VERSION ""

NS_ :

BS_:

BU_: Vector__XXX

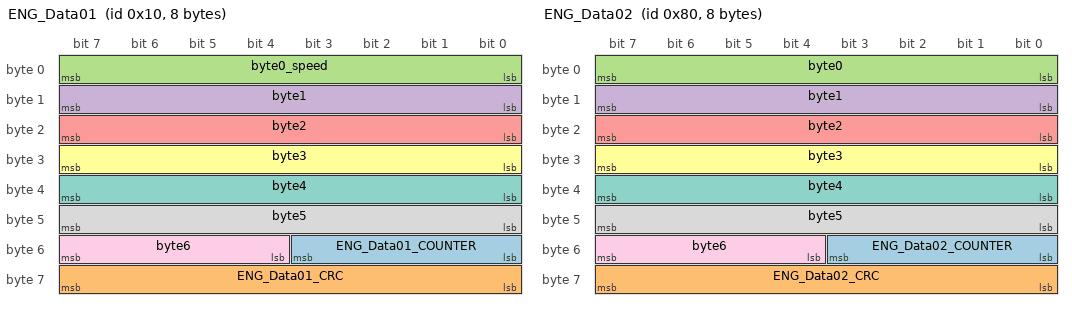
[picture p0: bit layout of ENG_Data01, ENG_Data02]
BO_ 16 ENG_Data01: 8 Vector__XXX
SG_ ENG_Data01_COUNTER : 51|4@0+ (1,0) [0|15] "" Vector__XXX
SG_ ENG_Data01_CRC : 63|8@0+ (1,0) [0|255] "" Vector__XXX
SG_ byte0_speed : 7|8@0+ (0.25,0) [0|63.75] "kmh" Vector__XXX
SG_ byte1 : 15|8@0+ (1,0) [0|255] "" Vector__XXX
SG_ byte2 : 23|8@0+ (1,0) [0|255] "" Vector__XXX
SG_ byte3 : 31|8@0+ (1,0) [0|255] "" Vector__XXX
SG_ byte4 : 39|8@0+ (1,0) [0|255] "" Vector__XXX
SG_ byte5 : 47|8@0+ (1,0) [0|255] "" Vector__XXX
SG_ byte6 : 55|4@0+ (1,0) [0|15] "" Vector__XXX

BO_ 128 ENG_Data02: 8 Vector__XXX
SG_ ENG_Data02_COUNTER : 51|4@0+ (1,0) [0|15] "" Vector__XXX
SG_ ENG_Data02_CRC : 63|8@0+ (1,0) [0|255] "" Vector__XXX
SG_ byte0 : 7|8@0+ (1,0) [0|255] "" Vector__XXX
SG_ byte1 : 15|8@0+ (1,0) [0|255] "" Vector__XXX
SG_ byte2 : 23|8@0+ (1,0) [0|255] "" Vector__XXX
SG_ byte3 : 31|8@0+ (1,0) [0|255] "" Vector__XXX
SG_ byte4 : 39|8@0+ (1,0) [0|255] "" Vector__XXX
SG_ byte5 : 47|8@0+ (1,0) [0|255] "" Vector__XXX
SG_ byte6 : 55|4@0+ (1,0) [0|15] "" Vector__XXX

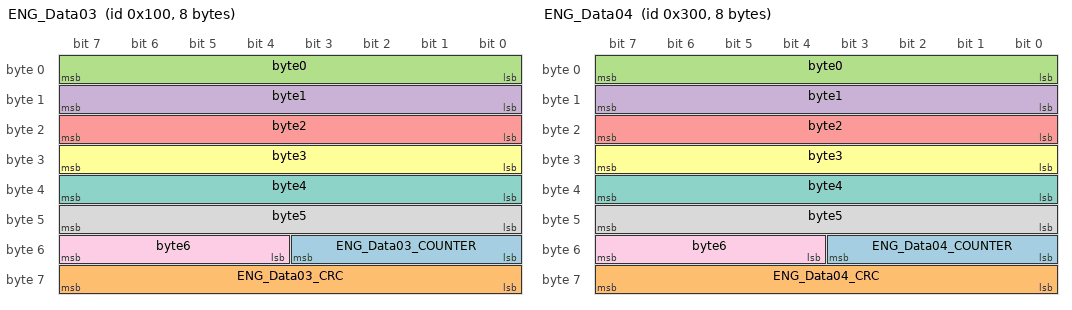
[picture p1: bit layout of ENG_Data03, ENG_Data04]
BO_ 256 ENG_Data03: 8 Vector__XXX
SG_ ENG_Data03_COUNTER : 51|4@0+ (1,0) [0|15] "" Vector__XXX
SG_ ENG_Data03_CRC : 63|8@0+ (1,0) [0|255] "" Vector__XXX
SG_ byte0 : 7|8@0+ (1,0) [0|255] "" Vector__XXX
SG_ byte1 : 15|8@0+ (1,0) [0|255] "" Vector__XXX
SG_ byte2 : 23|8@0+ (1,0) [0|255] "" Vector__XXX
SG_ byte3 : 31|8@0+ (1,0) [0|255] "" Vector__XXX
SG_ byte4 : 39|8@0+ (1,0) [0|255] "" Vector__XXX
SG_ byte5 : 47|8@0+ (1,0) [0|255] "" Vector__XXX
SG_ byte6 : 55|4@0+ (1,0) [0|15] "" Vector__XXX

BO_ 768 ENG_Data04: 8 Vector__XXX
SG_ ENG_Data04_COUNTER : 51|4@0+ (1,0) [0|15] "" Vector__XXX
SG_ ENG_Data04_CRC : 63|8@0+ (1,0) [0|255] "" Vector__XXX
SG_ byte0 : 7|8@0+ (1,0) [0|255] "" Vector__XXX
SG_ byte1 : 15|8@0+ (1,0) [0|255] "" Vector__XXX
SG_ byte2 : 23|8@0+ (1,0) [0|255] "" Vector__XXX
SG_ byte3 : 31|8@0+ (1,0) [0|255] "" Vector__XXX
SG_ byte4 : 39|8@0+ (1,0) [0|255] "" Vector__XXX
SG_ byte5 : 47|8@0+ (1,0) [0|255] "" Vector__XXX
SG_ byte6 : 55|4@0+ (1,0) [0|15] "" Vector__XXX

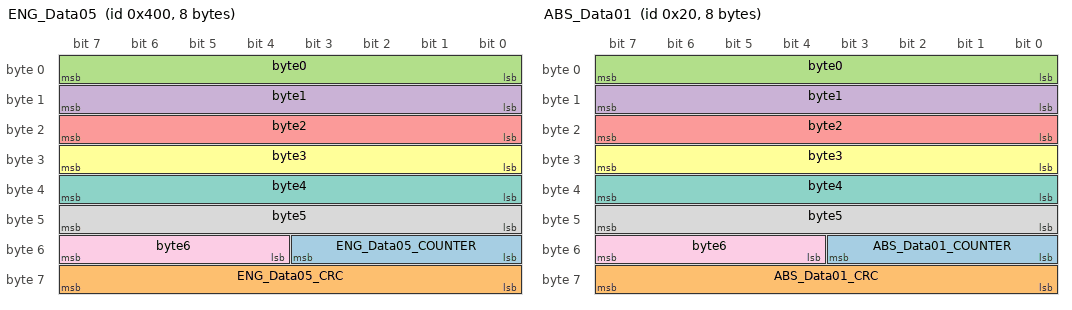
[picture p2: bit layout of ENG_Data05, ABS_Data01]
BO_ 1024 ENG_Data05: 8 Vector__XXX
SG_ ENG_Data05_COUNTER : 51|4@0+ (1,0) [0|15] "" Vector__XXX
SG_ ENG_Data05_CRC : 63|8@0+ (1,0) [0|255] "" Vector__XXX
SG_ byte0 : 7|8@0+ (1,0) [0|255] "" Vector__XXX
SG_ byte1 : 15|8@0+ (1,0) [0|255] "" Vector__XXX
SG_ byte2 : 23|8@0+ (1,0) [0|255] "" Vector__XXX
SG_ byte3 : 31|8@0+ (1,0) [0|255] "" Vector__XXX
SG_ byte4 : 39|8@0+ (1,0) [0|255] "" Vector__XXX
SG_ byte5 : 47|8@0+ (1,0) [0|255] "" Vector__XXX
SG_ byte6 : 55|4@0+ (1,0) [0|15] "" Vector__XXX

BO_ 32 ABS_Data01: 8 Vector__XXX
SG_ ABS_Data01_COUNTER : 51|4@0+ (1,0) [0|15] "" Vector__XXX
SG_ ABS_Data01_CRC : 63|8@0+ (1,0) [0|255] "" Vector__XXX
SG_ byte0 : 7|8@0+ (1,0) [0|255] "" Vector__XXX
SG_ byte1 : 15|8@0+ (1,0) [0|255] "" Vector__XXX
SG_ byte2 : 23|8@0+ (1,0) [0|255] "" Vector__XXX
SG_ byte3 : 31|8@0+ (1,0) [0|255] "" Vector__XXX
SG_ byte4 : 39|8@0+ (1,0) [0|255] "" Vector__XXX
SG_ byte5 : 47|8@0+ (1,0) [0|255] "" Vector__XXX
SG_ byte6 : 55|4@0+ (1,0) [0|15] "" Vector__XXX

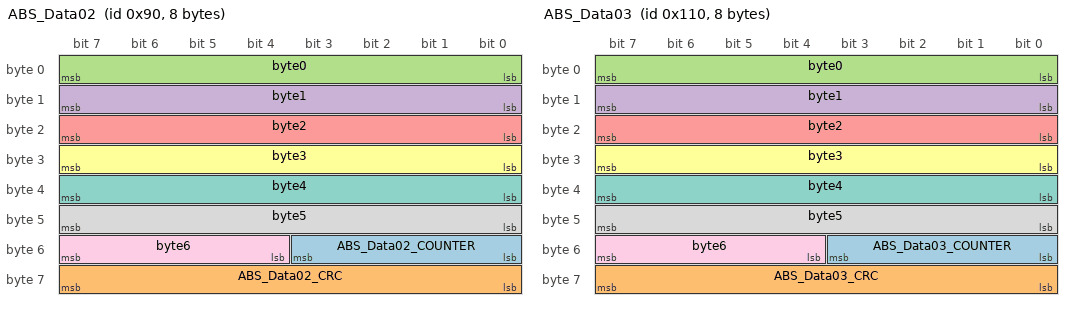
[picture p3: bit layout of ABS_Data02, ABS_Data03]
BO_ 144 ABS_Data02: 8 Vector__XXX
SG_ ABS_Data02_COUNTER : 51|4@0+ (1,0) [0|15] "" Vector__XXX
SG_ ABS_Data02_CRC : 63|8@0+ (1,0) [0|255] "" Vector__XXX
SG_ byte0 : 7|8@0+ (1,0) [0|255] "" Vector__XXX
SG_ byte1 : 15|8@0+ (1,0) [0|255] "" Vector__XXX
SG_ byte2 : 23|8@0+ (1,0) [0|255] "" Vector__XXX
SG_ byte3 : 31|8@0+ (1,0) [0|255] "" Vector__XXX
SG_ byte4 : 39|8@0+ (1,0) [0|255] "" Vector__XXX
SG_ byte5 : 47|8@0+ (1,0) [0|255] "" Vector__XXX
SG_ byte6 : 55|4@0+ (1,0) [0|15] "" Vector__XXX

BO_ 272 ABS_Data03: 8 Vector__XXX
SG_ ABS_Data03_COUNTER : 51|4@0+ (1,0) [0|15] "" Vector__XXX
SG_ ABS_Data03_CRC : 63|8@0+ (1,0) [0|255] "" Vector__XXX
SG_ byte0 : 7|8@0+ (1,0) [0|255] "" Vector__XXX
SG_ byte1 : 15|8@0+ (1,0) [0|255] "" Vector__XXX
SG_ byte2 : 23|8@0+ (1,0) [0|255] "" Vector__XXX
SG_ byte3 : 31|8@0+ (1,0) [0|255] "" Vector__XXX
SG_ byte4 : 39|8@0+ (1,0) [0|255] "" Vector__XXX
SG_ byte5 : 47|8@0+ (1,0) [0|255] "" Vector__XXX
SG_ byte6 : 55|4@0+ (1,0) [0|15] "" Vector__XXX

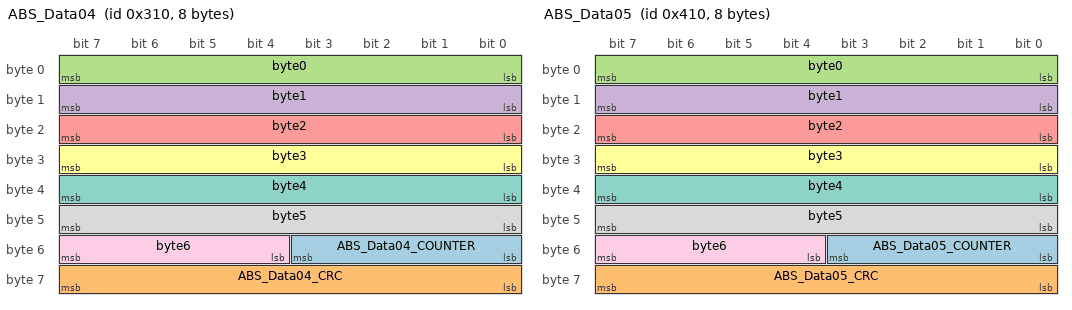
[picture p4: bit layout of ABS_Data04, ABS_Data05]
BO_ 784 ABS_Data04: 8 Vector__XXX
SG_ ABS_Data04_COUNTER : 51|4@0+ (1,0) [0|15] "" Vector__XXX
SG_ ABS_Data04_CRC : 63|8@0+ (1,0) [0|255] "" Vector__XXX
SG_ byte0 : 7|8@0+ (1,0) [0|255] "" Vector__XXX
SG_ byte1 : 15|8@0+ (1,0) [0|255] "" Vector__XXX
SG_ byte2 : 23|8@0+ (1,0) [0|255] "" Vector__XXX
SG_ byte3 : 31|8@0+ (1,0) [0|255] "" Vector__XXX
SG_ byte4 : 39|8@0+ (1,0) [0|255] "" Vector__XXX
SG_ byte5 : 47|8@0+ (1,0) [0|255] "" Vector__XXX
SG_ byte6 : 55|4@0+ (1,0) [0|15] "" Vector__XXX

BO_ 1040 ABS_Data05: 8 Vector__XXX
SG_ ABS_Data05_COUNTER : 51|4@0+ (1,0) [0|15] "" Vector__XXX
SG_ ABS_Data05_CRC : 63|8@0+ (1,0) [0|255] "" Vector__XXX
SG_ byte0 : 7|8@0+ (1,0) [0|255] "" Vector__XXX
SG_ byte1 : 15|8@0+ (1,0) [0|255] "" Vector__XXX
SG_ byte2 : 23|8@0+ (1,0) [0|255] "" Vector__XXX
SG_ byte3 : 31|8@0+ (1,0) [0|255] "" Vector__XXX
SG_ byte4 : 39|8@0+ (1,0) [0|255] "" Vector__XXX
SG_ byte5 : 47|8@0+ (1,0) [0|255] "" Vector__XXX
SG_ byte6 : 55|4@0+ (1,0) [0|15] "" Vector__XXX

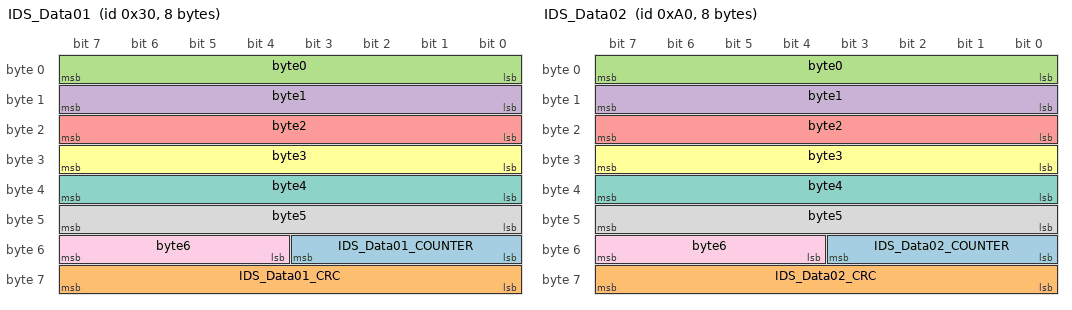
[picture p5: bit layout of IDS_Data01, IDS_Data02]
BO_ 48 IDS_Data01: 8 Vector__XXX
SG_ IDS_Data01_COUNTER : 51|4@0+ (1,0) [0|15] "" Vector__XXX
SG_ IDS_Data01_CRC : 63|8@0+ (1,0) [0|255] "" Vector__XXX
SG_ byte0 : 7|8@0+ (1,0) [0|255] "" Vector__XXX
SG_ byte1 : 15|8@0+ (1,0) [0|255] "" Vector__XXX
SG_ byte2 : 23|8@0+ (1,0) [0|255] "" Vector__XXX
SG_ byte3 : 31|8@0+ (1,0) [0|255] "" Vector__XXX
SG_ byte4 : 39|8@0+ (1,0) [0|255] "" Vector__XXX
SG_ byte5 : 47|8@0+ (1,0) [0|255] "" Vector__XXX
SG_ byte6 : 55|4@0+ (1,0) [0|15] "" Vector__XXX

BO_ 160 IDS_Data02: 8 Vector__XXX
SG_ IDS_Data02_COUNTER : 51|4@0+ (1,0) [0|15] "" Vector__XXX
SG_ IDS_Data02_CRC : 63|8@0+ (1,0) [0|255] "" Vector__XXX
SG_ byte0 : 7|8@0+ (1,0) [0|255] "" Vector__XXX
SG_ byte1 : 15|8@0+ (1,0) [0|255] "" Vector__XXX
SG_ byte2 : 23|8@0+ (1,0) [0|255] "" Vector__XXX
SG_ byte3 : 31|8@0+ (1,0) [0|255] "" Vector__XXX
SG_ byte4 : 39|8@0+ (1,0) [0|255] "" Vector__XXX
SG_ byte5 : 47|8@0+ (1,0) [0|255] "" Vector__XXX
SG_ byte6 : 55|4@0+ (1,0) [0|15] "" Vector__XXX

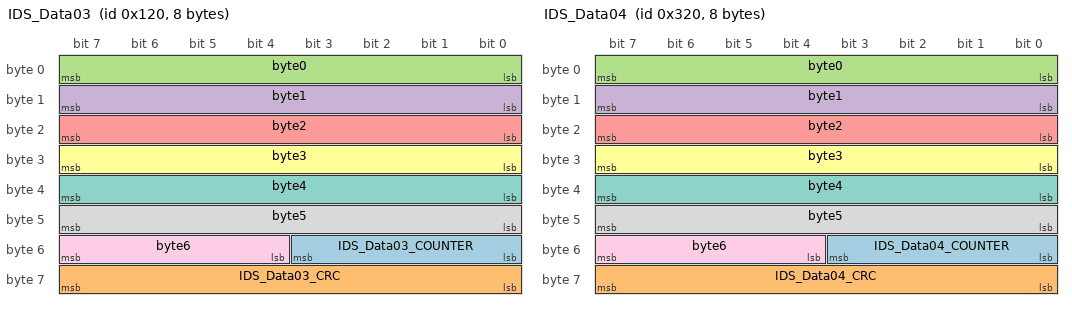
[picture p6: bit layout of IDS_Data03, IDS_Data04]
BO_ 288 IDS_Data03: 8 Vector__XXX
SG_ IDS_Data03_COUNTER : 51|4@0+ (1,0) [0|15] "" Vector__XXX
SG_ IDS_Data03_CRC : 63|8@0+ (1,0) [0|255] "" Vector__XXX
SG_ byte0 : 7|8@0+ (1,0) [0|255] "" Vector__XXX
SG_ byte1 : 15|8@0+ (1,0) [0|255] "" Vector__XXX
SG_ byte2 : 23|8@0+ (1,0) [0|255] "" Vector__XXX
SG_ byte3 : 31|8@0+ (1,0) [0|255] "" Vector__XXX
SG_ byte4 : 39|8@0+ (1,0) [0|255] "" Vector__XXX
SG_ byte5 : 47|8@0+ (1,0) [0|255] "" Vector__XXX
SG_ byte6 : 55|4@0+ (1,0) [0|15] "" Vector__XXX

BO_ 800 IDS_Data04: 8 Vector__XXX
SG_ IDS_Data04_COUNTER : 51|4@0+ (1,0) [0|15] "" Vector__XXX
SG_ IDS_Data04_CRC : 63|8@0+ (1,0) [0|255] "" Vector__XXX
SG_ byte0 : 7|8@0+ (1,0) [0|255] "" Vector__XXX
SG_ byte1 : 15|8@0+ (1,0) [0|255] "" Vector__XXX
SG_ byte2 : 23|8@0+ (1,0) [0|255] "" Vector__XXX
SG_ byte3 : 31|8@0+ (1,0) [0|255] "" Vector__XXX
SG_ byte4 : 39|8@0+ (1,0) [0|255] "" Vector__XXX
SG_ byte5 : 47|8@0+ (1,0) [0|255] "" Vector__XXX
SG_ byte6 : 55|4@0+ (1,0) [0|15] "" Vector__XXX

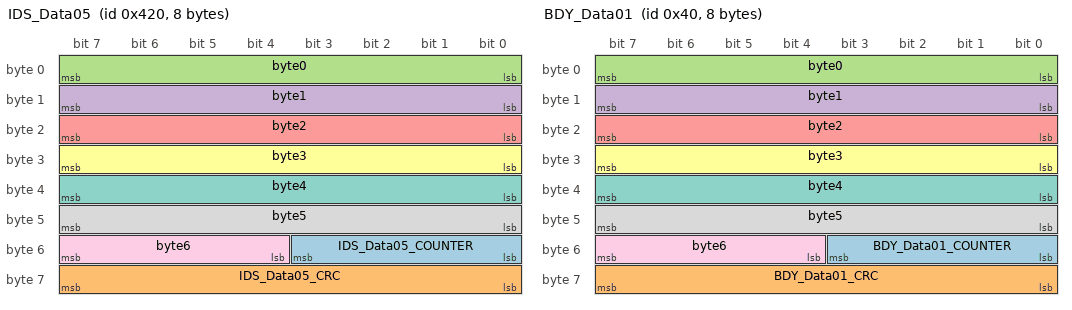
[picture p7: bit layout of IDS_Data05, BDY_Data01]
BO_ 1056 IDS_Data05: 8 Vector__XXX
SG_ IDS_Data05_COUNTER : 51|4@0+ (1,0) [0|15] "" Vector__XXX
SG_ IDS_Data05_CRC : 63|8@0+ (1,0) [0|255] "" Vector__XXX
SG_ byte0 : 7|8@0+ (1,0) [0|255] "" Vector__XXX
SG_ byte1 : 15|8@0+ (1,0) [0|255] "" Vector__XXX
SG_ byte2 : 23|8@0+ (1,0) [0|255] "" Vector__XXX
SG_ byte3 : 31|8@0+ (1,0) [0|255] "" Vector__XXX
SG_ byte4 : 39|8@0+ (1,0) [0|255] "" Vector__XXX
SG_ byte5 : 47|8@0+ (1,0) [0|255] "" Vector__XXX
SG_ byte6 : 55|4@0+ (1,0) [0|15] "" Vector__XXX

BO_ 64 BDY_Data01: 8 Vector__XXX
SG_ BDY_Data01_COUNTER : 51|4@0+ (1,0) [0|15] "" Vector__XXX
SG_ BDY_Data01_CRC : 63|8@0+ (1,0) [0|255] "" Vector__XXX
SG_ byte0 : 7|8@0+ (1,0) [0|255] "" Vector__XXX
SG_ byte1 : 15|8@0+ (1,0) [0|255] "" Vector__XXX
SG_ byte2 : 23|8@0+ (1,0) [0|255] "" Vector__XXX
SG_ byte3 : 31|8@0+ (1,0) [0|255] "" Vector__XXX
SG_ byte4 : 39|8@0+ (1,0) [0|255] "" Vector__XXX
SG_ byte5 : 47|8@0+ (1,0) [0|255] "" Vector__XXX
SG_ byte6 : 55|4@0+ (1,0) [0|15] "" Vector__XXX

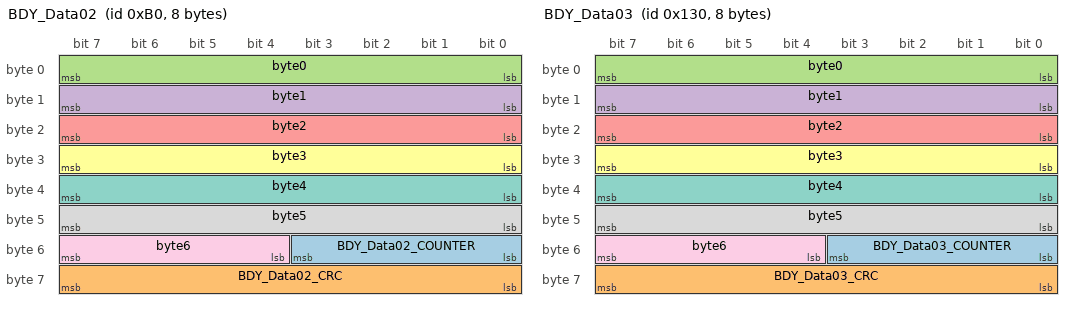
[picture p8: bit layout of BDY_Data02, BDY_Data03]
BO_ 176 BDY_Data02: 8 Vector__XXX
SG_ BDY_Data02_COUNTER : 51|4@0+ (1,0) [0|15] "" Vector__XXX
SG_ BDY_Data02_CRC : 63|8@0+ (1,0) [0|255] "" Vector__XXX
SG_ byte0 : 7|8@0+ (1,0) [0|255] "" Vector__XXX
SG_ byte1 : 15|8@0+ (1,0) [0|255] "" Vector__XXX
SG_ byte2 : 23|8@0+ (1,0) [0|255] "" Vector__XXX
SG_ byte3 : 31|8@0+ (1,0) [0|255] "" Vector__XXX
SG_ byte4 : 39|8@0+ (1,0) [0|255] "" Vector__XXX
SG_ byte5 : 47|8@0+ (1,0) [0|255] "" Vector__XXX
SG_ byte6 : 55|4@0+ (1,0) [0|15] "" Vector__XXX

BO_ 304 BDY_Data03: 8 Vector__XXX
SG_ BDY_Data03_COUNTER : 51|4@0+ (1,0) [0|15] "" Vector__XXX
SG_ BDY_Data03_CRC : 63|8@0+ (1,0) [0|255] "" Vector__XXX
SG_ byte0 : 7|8@0+ (1,0) [0|255] "" Vector__XXX
SG_ byte1 : 15|8@0+ (1,0) [0|255] "" Vector__XXX
SG_ byte2 : 23|8@0+ (1,0) [0|255] "" Vector__XXX
SG_ byte3 : 31|8@0+ (1,0) [0|255] "" Vector__XXX
SG_ byte4 : 39|8@0+ (1,0) [0|255] "" Vector__XXX
SG_ byte5 : 47|8@0+ (1,0) [0|255] "" Vector__XXX
SG_ byte6 : 55|4@0+ (1,0) [0|15] "" Vector__XXX

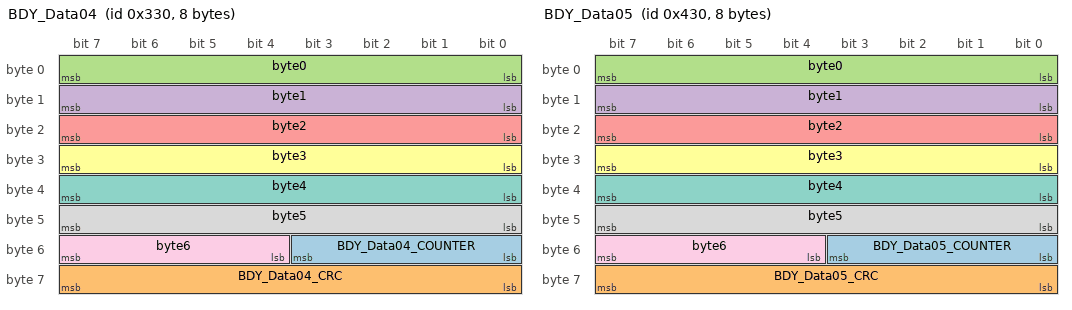
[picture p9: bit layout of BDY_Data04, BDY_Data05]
BO_ 816 BDY_Data04: 8 Vector__XXX
SG_ BDY_Data04_COUNTER : 51|4@0+ (1,0) [0|15] "" Vector__XXX
SG_ BDY_Data04_CRC : 63|8@0+ (1,0) [0|255] "" Vector__XXX
SG_ byte0 : 7|8@0+ (1,0) [0|255] "" Vector__XXX
SG_ byte1 : 15|8@0+ (1,0) [0|255] "" Vector__XXX
SG_ byte2 : 23|8@0+ (1,0) [0|255] "" Vector__XXX
SG_ byte3 : 31|8@0+ (1,0) [0|255] "" Vector__XXX
SG_ byte4 : 39|8@0+ (1,0) [0|255] "" Vector__XXX
SG_ byte5 : 47|8@0+ (1,0) [0|255] "" Vector__XXX
SG_ byte6 : 55|4@0+ (1,0) [0|15] "" Vector__XXX

BO_ 1072 BDY_Data05: 8 Vector__XXX
SG_ BDY_Data05_COUNTER : 51|4@0+ (1,0) [0|15] "" Vector__XXX
SG_ BDY_Data05_CRC : 63|8@0+ (1,0) [0|255] "" Vector__XXX
SG_ byte0 : 7|8@0+ (1,0) [0|255] "" Vector__XXX
SG_ byte1 : 15|8@0+ (1,0) [0|255] "" Vector__XXX
SG_ byte2 : 23|8@0+ (1,0) [0|255] "" Vector__XXX
SG_ byte3 : 31|8@0+ (1,0) [0|255] "" Vector__XXX
SG_ byte4 : 39|8@0+ (1,0) [0|255] "" Vector__XXX
SG_ byte5 : 47|8@0+ (1,0) [0|255] "" Vector__XXX
SG_ byte6 : 55|4@0+ (1,0) [0|15] "" Vector__XXX

BA_DEF_  "BusType" STRING ;
BA_DEF_ BO_  "GenMsgCycleTime" INT 0 65535;
BA_DEF_ SG_  "GenSigStartValue" INT 0 65535;

BA_DEF_DEF_  "BusType" "CAN";
BA_DEF_DEF_  "GenMsgCycleTime" 0;
BA_DEF_DEF_  "GenSigStartValue" 0;

BA_ "GenMsgCycleTime" BO_ 16 10;
BA_ "GenMsgCycleTime" BO_ 128 10;
BA_ "GenMsgCycleTime" BO_ 256 100;
BA_ "GenMsgCycleTime" BO_ 768 100;
BA_ "GenMsgCycleTime" BO_ 1024 500;
BA_ "GenMsgCycleTime" BO_ 32 10;
BA_ "GenMsgCycleTime" BO_ 144 10;
BA_ "GenMsgCycleTime" BO_ 272 100;
BA_ "GenMsgCycleTime" BO_ 784 100;
BA_ "GenMsgCycleTime" BO_ 1040 500;
BA_ "GenMsgCycleTime" BO_ 48 10;
BA_ "GenMsgCycleTime" BO_ 160 10;
BA_ "GenMsgCycleTime" BO_ 288 100;
BA_ "GenMsgCycleTime" BO_ 800 100;
BA_ "GenMsgCycleTime" BO_ 1056 500;
BA_ "GenMsgCycleTime" BO_ 64 10;
BA_ "GenMsgCycleTime" BO_ 176 10;
BA_ "GenMsgCycleTime" BO_ 304 100;
BA_ "GenMsgCycleTime" BO_ 816 100;
BA_ "GenMsgCycleTime" BO_ 1072 500;
